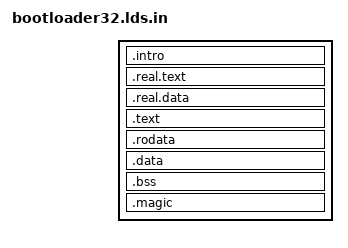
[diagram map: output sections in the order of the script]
OUTPUT_FORMAT(elf32-i386)

SECTIONS
{
    . = @F_BOOTLOADER_MEMORY_LOCATION@;

    .intro :
    {
        KEEP(*(.intro))
    }

    .real.text :
    {
        *(.real.text*)
    }

    . = ALIGN(0x200);

    .real.data :
    {
        *(.real.data*)
    }

    . = ALIGN(0x200);

    .text :
    {
        *(.text*)
    }

    . = ALIGN(0x200);

    .rodata :
    {
        *(.rodata*)
    }

    . = ALIGN(0x200);

    .data :
    {
        *(.data*)
    }

    . = ALIGN(0x200);

    .bss :
    {
        *(.bss*)
    }

    . = @F_BOOTLOADER_MEMORY_LOCATION@ + @F_BOOTLOADER_SIZE_IN_SECTORS@ * 0x200 - 4;

    .magic :
    {
        LONG(@F_BOOTLOADER_MAGIC@);
    }

    HEAP_START = .;
    . = ADDR(.bss) + SIZEOF(.bss);
}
